# STM32H757_CM7 register map
File version: 1.3
CPU: CM7 r0p1, little endian, MPU, FPU, 4 interrupt priority bits
Registers are 32-bit, read-write, reset 0x0 unless marked. A register's access mark holds for its fields unless they carry their own. Offsets are from the block's base; [hi:lo] are bit positions.

## VREFBUF
Base 0x58003C00
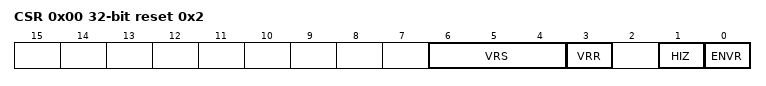
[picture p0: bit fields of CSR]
0x00 CSR access per field reset 0x2 — VREFBUF control and status register
  [6:4] VRS rw — Voltage reference scale These bits select the value generated by the voltage reference buffer. Other: Reserved
  [3] VRR ro — Voltage reference buffer ready
  [1] HIZ rw — High impedance mode This bit controls the analog switch to connect or not the VREF+ pin. Refer to Table196: VREF buffer modes for the mode descriptions depending on ENVR bit configuration.
  [0] ENVR rw — Voltage reference buffer mode enable This bit is used to enable the voltage reference buffer mode.
0x04 CCR — VREFBUF calibration control register
  [5:0] TRIM — Trimming code These bits are automatically initialized after reset with the trimming value stored in the Flash memory during the production test. Writing into these bits allows to tune the internal reference buffer voltage.

## WWDG1 — WWDG
Base 0x50003000
Same registers: WWDG2 0x40002C00
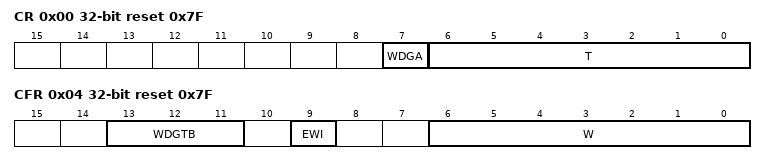
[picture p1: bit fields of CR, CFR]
0x00 CR reset 0x7F — Control register
  [7] WDGA — Activation bit This bit is set by software and only cleared by hardware after a reset. When WDGA=1, the watchdog can generate a reset.
    0=Disabled (Watchdog disabled); 1=Enabled (Watchdog enabled)
  [6:0] T — 7-bit counter (MSB to LSB) These bits contain the value of the watchdog counter. It is decremented every (4096 x 2WDGTB[1:0]) PCLK cycles. A reset is produced when it is decremented from 0x40 to 0x3F (T6 becomes cleared).
0x04 CFR reset 0x7F — Configuration register
  [13:11] WDGTB — Timer base The time base of the prescaler can be modified as follows:
    4=Div16 (Counter clock (PCLK1 div 4096) div 16); 5=Div32 (Counter clock (PCLK1 div 4096) div 32); 6=Div64 (Counter clock (PCLK1 div 4096) div 64); 7=Div128 (Counter clock (PCLK1 div 4096) div 128); 0=Div1 (Counter clock (PCLK1 div 4096) div 1); 1=Div2 (Counter clock (PCLK1 div 4096) div 2); 2=Div4 (Counter clock (PCLK1 div 4096) div 4); 3=Div8 (Counter clock (PCLK1 div 4096) div 8)
  [9] EWI — Early wakeup interrupt When set, an interrupt occurs whenever the counter reaches the value 0x40. This interrupt is only cleared by hardware after a reset.
    on write: 1=Enable (interrupt occurs whenever the counter reaches the value 0x40)
  [6:0] W — 7-bit window value These bits contain the window value to be compared to the downcounter.
0x08 SR — Status register
  [0] EWIF — Early wakeup interrupt flag This bit is set by hardware when the counter has reached the value 0x40. It must be cleared by software by writing 0. A write of 1 has no effect. This bit is also set if the interrupt is not enabled.
    on read: 1=Pending (The EWI Interrupt Service Routine has been triggered); 0=Finished (The EWI Interrupt Service Routine has been serviced) | on write: 0=Finished (The EWI Interrupt Service Routine has been serviced)

## SPDIFRX — Receiver Interface
Base 0x40004000
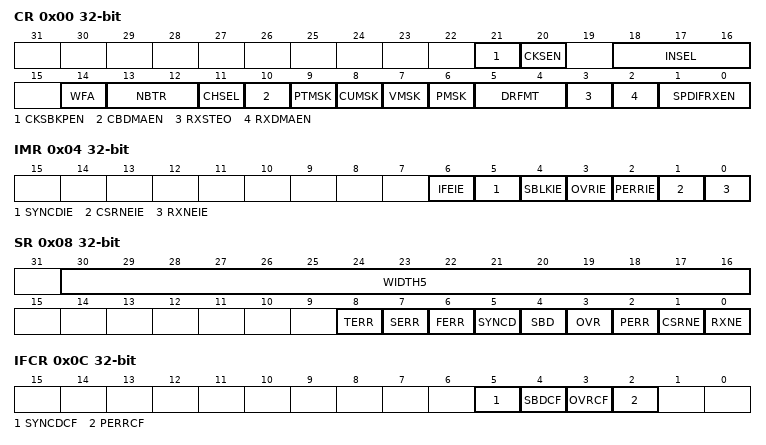
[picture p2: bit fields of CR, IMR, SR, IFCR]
0x00 CR — Control register
  [21] CKSBKPEN — Backup Symbol Clock Enable
  [20] CKSEN — Symbol Clock Enable
  [18:16] INSEL — input selection
  [14] WFA — Wait For Activity
  [13:12] NBTR — Maximum allowed re-tries during synchronization phase
  [11] CHSEL — Channel Selection
  [10] CBDMAEN — Control Buffer DMA ENable for control flow
  [9] PTMSK — Mask of Preamble Type bits
  [8] CUMSK — Mask of channel status and user bits
  [7] VMSK — Mask of Validity bit
  [6] PMSK — Mask Parity error bit
  [5:4] DRFMT — RX Data format
  [3] RXSTEO — STerEO Mode
  [2] RXDMAEN — Receiver DMA ENable for data flow
  [1:0] SPDIFRXEN — Peripheral Block Enable
0x04 IMR — Interrupt mask register
  [6] IFEIE — Serial Interface Error Interrupt Enable
  [5] SYNCDIE — Synchronization Done
  [4] SBLKIE — Synchronization Block Detected Interrupt Enable
  [3] OVRIE — Overrun error Interrupt Enable
  [2] PERRIE — Parity error interrupt enable
  [1] CSRNEIE — Control Buffer Ready Interrupt Enable
  [0] RXNEIE — RXNE interrupt enable
0x08 SR ro — Status register
  [30:16] WIDTH5 — Duration of 5 symbols counted with SPDIF_CLK
  [8] TERR — Time-out error
  [7] SERR — Synchronization error
  [6] FERR — Framing error
  [5] SYNCD — Synchronization Done
  [4] SBD — Synchronization Block Detected
  [3] OVR — Overrun error
  [2] PERR — Parity error
  [1] CSRNE — Control Buffer register is not empty
  [0] RXNE — Read data register not empty
0x0C IFCR wo — Interrupt Flag Clear register
  [5] SYNCDCF — Clears the Synchronization Done flag
  [4] SBDCF — Clears the Synchronization Block Detected flag
  [3] OVRCF — Clears the Overrun error flag
  [2] PERRCF — Clears the Parity error flag
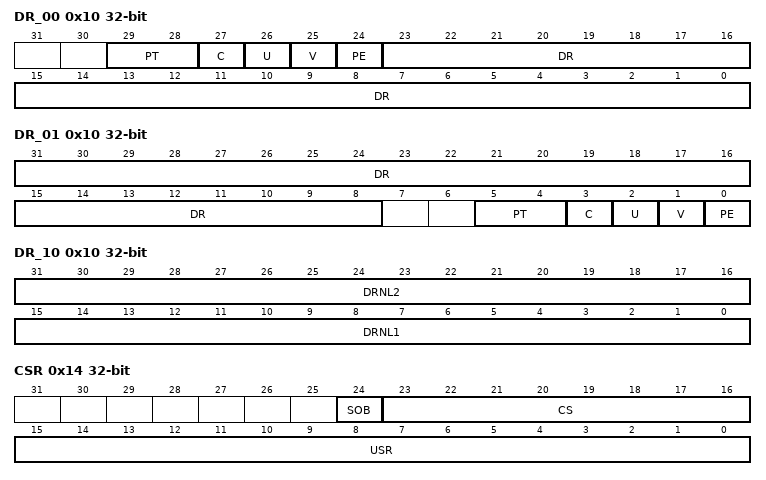
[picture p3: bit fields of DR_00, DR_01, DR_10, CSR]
0x10 DR_00 ro — Data input register
  [29:28] PT — Preamble Type
  [27] C — Channel Status bit
  [26] U — User bit
  [25] V — Validity bit
  [24] PE — Parity Error bit
  [23:0] DR — Parity Error bit
0x10 DR_01 ro (alternate view of DR_00) — Data input register
  [31:8] DR — Data value
  [5:4] PT — Preamble Type
  [3] C — Channel Status bit
  [2] U — User bit
  [1] V — Validity bit
  [0] PE — Parity Error bit
0x10 DR_10 ro — Data input register
  [31:16] DRNL2 — Data value
  [15:0] DRNL1 — Data value
0x14 CSR ro — Channel Status register
  [24] SOB — Start Of Block
  [23:16] CS — Channel A status information
  [15:0] USR — User data information
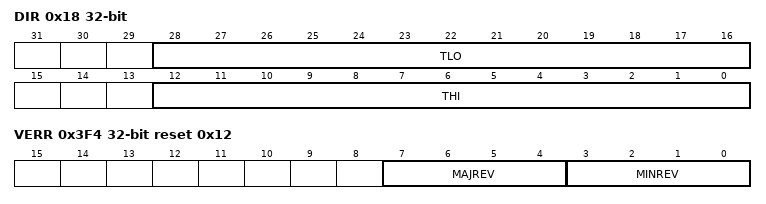
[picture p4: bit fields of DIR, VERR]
0x18 DIR ro — Debug Information register
  [28:16] TLO — Threshold LOW
  [12:0] THI — Threshold HIGH
0x3F4 VERR ro reset 0x12 — SPDIFRX version register
  [7:4] MAJREV — Major revision
  [3:0] MINREV — Minor revision
0x3F8 IDR ro reset 0x130041 — SPDIFRX identification register
  [31:0] ID — SPDIFRX identifier
0x3FC SIDR ro reset 0xA3C5DD01 — SPDIFRX size identification register
  [31:0] SID — Size identification
